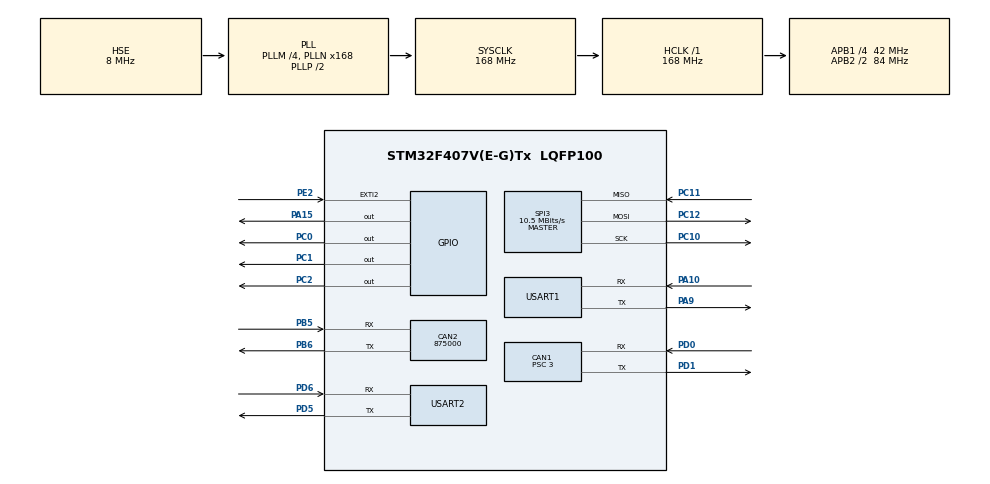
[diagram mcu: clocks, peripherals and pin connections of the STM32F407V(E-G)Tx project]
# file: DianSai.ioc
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CAN1.ABOM=DISABLE
CAN1.BS1=CAN_BS1_10TQ
CAN1.BS2=CAN_BS2_3TQ
CAN1.CalculateBaudRate=1000000
CAN1.CalculateTimeBit=1000
CAN1.CalculateTimeQuantum=71.42857142857143
CAN1.NART=DISABLE
CAN1.Prescaler=3
CAN1.SJW=CAN_SJW_1TQ
CAN2.BS1=CAN_BS1_1TQ
CAN2.BS2=CAN_BS2_1TQ
CAN2.CalculateBaudRate=875000
CAN2.CalculateTimeBit=1142
CAN2.CalculateTimeQuantum=380.95238095238096
Dma.Request0=USART1_TX
Dma.Request1=USART2_RX
Dma.Request2=USART2_TX
Dma.USART1_TX.0.Direction=DMA_MEMORY_TO_PERIPH
Dma.USART1_TX.0.FIFOMode=DMA_FIFOMODE_DISABLE
Dma.USART1_TX.0.Instance=DMA2_Stream7
Dma.USART1_TX.0.MemDataAlignment=DMA_MDATAALIGN_BYTE
Dma.USART1_TX.0.MemInc=DMA_MINC_ENABLE
Dma.USART1_TX.0.Mode=DMA_NORMAL
Dma.USART1_TX.0.PeriphDataAlignment=DMA_PDATAALIGN_BYTE
Dma.USART1_TX.0.PeriphInc=DMA_PINC_DISABLE
Dma.USART1_TX.0.Priority=DMA_PRIORITY_LOW
Dma.USART2_RX.1.Direction=DMA_PERIPH_TO_MEMORY
Dma.USART2_RX.1.FIFOMode=DMA_FIFOMODE_DISABLE
Dma.USART2_RX.1.Instance=DMA1_Stream5
Dma.USART2_RX.1.MemDataAlignment=DMA_MDATAALIGN_BYTE
Dma.USART2_RX.1.MemInc=DMA_MINC_ENABLE
Dma.USART2_RX.1.Mode=DMA_NORMAL
Dma.USART2_RX.1.PeriphDataAlignment=DMA_PDATAALIGN_BYTE
Dma.USART2_RX.1.PeriphInc=DMA_PINC_DISABLE
Dma.USART2_RX.1.Priority=DMA_PRIORITY_LOW
Dma.USART2_TX.2.Direction=DMA_MEMORY_TO_PERIPH
Dma.USART2_TX.2.FIFOMode=DMA_FIFOMODE_DISABLE
Dma.USART2_TX.2.Instance=DMA1_Stream6
Dma.USART2_TX.2.MemDataAlignment=DMA_MDATAALIGN_BYTE
Dma.USART2_TX.2.MemInc=DMA_MINC_ENABLE
Dma.USART2_TX.2.Mode=DMA_NORMAL
Dma.USART2_TX.2.PeriphDataAlignment=DMA_PDATAALIGN_BYTE
Dma.USART2_TX.2.PeriphInc=DMA_PINC_DISABLE
Dma.USART2_TX.2.Priority=DMA_PRIORITY_LOW
FREERTOS.Tasks01=defaultTask,0,128,StartDefaultTask,Default,NULL,Dynamic,NULL,NULL
Mcu.Family=STM32F4
Mcu.Name=STM32F407V(E-G)Tx
Mcu.Package=LQFP100
NVIC.CAN1_RX0_IRQn=true\:5\:0\:false\:false\:true\:true\:true\:true\:true
NVIC.CAN1_RX1_IRQn=true\:5\:0\:false\:false\:true\:true\:true\:true\:true
NVIC.CAN1_SCE_IRQn=true\:5\:0\:false\:false\:true\:true\:true\:true\:true
NVIC.CAN1_TX_IRQn=true\:5\:0\:false\:false\:true\:true\:true\:true\:true
NVIC.CAN2_RX0_IRQn=true\:5\:0\:true\:false\:true\:true\:true\:true\:true
NVIC.DMA1_Stream5_IRQn=true\:5\:0\:false\:false\:true\:true\:false\:true\:true
NVIC.DMA1_Stream6_IRQn=true\:5\:0\:false\:false\:true\:true\:false\:true\:true
NVIC.DMA2_Stream7_IRQn=true\:5\:0\:false\:false\:true\:true\:false\:true\:true
NVIC.EXTI2_IRQn=true\:6\:0\:true\:false\:true\:true\:true\:true\:true
NVIC.PriorityGroup=NVIC_PRIORITYGROUP_4
NVIC.TIM8_TRG_COM_TIM14_IRQn=true\:5\:0\:true\:false\:true\:false\:false\:true\:true
NVIC.TimeBase=TIM8_TRG_COM_TIM14_IRQn
NVIC.TimeBaseIP=TIM14
NVIC.USART1_IRQn=true\:5\:0\:false\:false\:true\:true\:true\:true\:true
NVIC.USART2_IRQn=true\:5\:0\:false\:false\:true\:true\:true\:true\:true
PA10.Mode=Asynchronous
PA10.Signal=USART1_RX
PA13.Mode=Serial_Wire
PA13.Signal=SYS_JTMS-SWDIO
PA14.Mode=Serial_Wire
PA14.Signal=SYS_JTCK-SWCLK
PA15.GPIO_Speed=GPIO_SPEED_FREQ_HIGH
PA15.Signal=GPIO_Output
PA9.Mode=Asynchronous
PA9.Signal=USART1_TX
PB5.Mode=CAN_Activate
PB5.Signal=CAN2_RX
PB6.Mode=CAN_Activate
PB6.Signal=CAN2_TX
PC0.Signal=GPIO_Output
PC1.Signal=GPIO_Output
PC10.Mode=Full_Duplex_Master
PC10.Signal=SPI3_SCK
PC11.Mode=Full_Duplex_Master
PC11.Signal=SPI3_MISO
PC12.Mode=Full_Duplex_Master
PC12.Signal=SPI3_MOSI
PC2.Signal=GPIO_Output
PD0.Mode=CAN_Activate
PD0.Signal=CAN1_RX
PD1.Mode=CAN_Activate
PD1.Signal=CAN1_TX
PD5.Mode=Asynchronous
PD5.Signal=USART2_TX
PD6.Mode=Asynchronous
PD6.Signal=USART2_RX
PE2.GPIO_ModeDefaultEXTI=GPIO_MODE_IT_RISING
PE2.GPIO_PuPd=GPIO_PULLUP
PE2.Signal=GPXTI2
PH0-OSC_IN.Mode=HSE-External-Oscillator
PH0-OSC_IN.Signal=RCC_OSC_IN
PH1-OSC_OUT.Mode=HSE-External-Oscillator
PH1-OSC_OUT.Signal=RCC_OSC_OUT
ProjectManager.HeapSize=0x200
ProjectManager.StackSize=0x400
ProjectManager.TargetToolchain=MDK-ARM V5.32
RCC.48MHZClocksFreq_Value=84000000
RCC.AHBFreq_Value=168000000
RCC.APB1CLKDivider=RCC_HCLK_DIV4
RCC.APB1Freq_Value=42000000
RCC.APB1TimFreq_Value=84000000
RCC.APB2CLKDivider=RCC_HCLK_DIV2
RCC.APB2Freq_Value=84000000
RCC.APB2TimFreq_Value=168000000
RCC.CortexFreq_Value=168000000
RCC.HCLKFreq_Value=168000000
RCC.HSE_VALUE=8000000
RCC.HSI_VALUE=16000000
RCC.LSE_VALUE=32768
RCC.PLLM=4
RCC.PLLN=168
RCC.PLLSourceVirtual=RCC_PLLSOURCE_HSE
RCC.SYSCLKFreq_VALUE=168000000
RCC.SYSCLKSource=RCC_SYSCLKSOURCE_PLLCLK
RCC.VCOOutputFreq_Value=336000000
SPI3.BaudRatePrescaler=SPI_BAUDRATEPRESCALER_4
SPI3.CalculateBaudRate=10.5 MBits/s
SPI3.Direction=SPI_DIRECTION_2LINES
SPI3.Mode=SPI_MODE_MASTER
SPI3.VirtualType=VM_MASTER
STMicroelectronics.X-CUBE-ALGOBUILD.1.5.0.LibraryCcDSPOoLibraryJjDSPOoLibrary=true
USART1.VirtualMode=VM_ASYNC
USART2.VirtualMode=VM_ASYNC
VP_FREERTOS_VS_CMSIS_V1.Mode=CMSIS_V1
VP_STMicroelectronics.X-CUBE-ALGOBUILD_VS_DSPOoLibraryJjLibrary_1.5.0_1.5.0.Mode=DSPOoLibraryJjLibrary
VP_SYS_VS_tim14.Mode=TIM14
board=custom

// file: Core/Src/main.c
/* USER CODE BEGIN Header */
/**
  ******************************************************************************
  * @file           : main.c
  * @brief          : Main program body
  ******************************************************************************
  * @attention
  *
  * Copyright (c) 2026 STMicroelectronics.
  * All rights reserved.
  *
  * This software is licensed under terms that can be found in the LICENSE file
  * in the root directory of this software component.
  * If no LICENSE file comes with this software, it is provided AS-IS.
  *
  ******************************************************************************
  */
/* USER CODE END Header */
#include "main.h"
#include "cmsis_os.h"
#include "can.h"
#include "dma.h"
#include "spi.h"
#include "usart.h"
#include "gpio.h"

/* USER CODE BEGIN Includes */
#include "main_task.h"
/* USER CODE END Includes */

void SystemClock_Config(void);
void MX_FREERTOS_Init(void);

int main(void)
{

  /* MCU Configuration--------------------------------------------------------*/

  /* Reset of all peripherals, Initializes the Flash interface and the Systick. */
  HAL_Init();

  /* Configure the system clock */
  SystemClock_Config();

  /* Initialize all configured peripherals */
  MX_GPIO_Init();
  MX_DMA_Init();
  MX_CAN1_Init();
  MX_CAN2_Init();
  MX_USART1_UART_Init();
  MX_USART2_UART_Init();
  MX_SPI3_Init();
  /* USER CODE BEGIN 2 */

  main_task_init();
  /* USER CODE END 2 */

  /* Call init function for freertos objects (in cmsis_os2.c) */
  MX_FREERTOS_Init();

  /* Start scheduler */
  osKernelStart();

  /* We should never get here as control is now taken by the scheduler */

  /* Infinite loop */
  while (1)
  {

  }
}

void SystemClock_Config(void)
{
  RCC_OscInitTypeDef RCC_OscInitStruct = {0};
  RCC_ClkInitTypeDef RCC_ClkInitStruct = {0};

  /** Configure the main internal regulator output voltage
  */
  __HAL_RCC_PWR_CLK_ENABLE();
  __HAL_PWR_VOLTAGESCALING_CONFIG(PWR_REGULATOR_VOLTAGE_SCALE1);

  /** Initializes the RCC Oscillators according to the specified parameters
  * in the RCC_OscInitTypeDef structure.
  */
  RCC_OscInitStruct.OscillatorType = RCC_OSCILLATORTYPE_HSE;
  RCC_OscInitStruct.HSEState = RCC_HSE_ON;
  RCC_OscInitStruct.PLL.PLLState = RCC_PLL_ON;
  RCC_OscInitStruct.PLL.PLLSource = RCC_PLLSOURCE_HSE;
  RCC_OscInitStruct.PLL.PLLM = 4;
  RCC_OscInitStruct.PLL.PLLN = 168;
  RCC_OscInitStruct.PLL.PLLP = RCC_PLLP_DIV2;
  RCC_OscInitStruct.PLL.PLLQ = 4;
  if (HAL_RCC_OscConfig(&RCC_OscInitStruct) != HAL_OK)
  {
    Error_Handler();
  }

  /** Initializes the CPU, AHB and APB buses clocks
  */
  RCC_ClkInitStruct.ClockType = RCC_CLOCKTYPE_HCLK|RCC_CLOCKTYPE_SYSCLK
                              |RCC_CLOCKTYPE_PCLK1|RCC_CLOCKTYPE_PCLK2;
  RCC_ClkInitStruct.SYSCLKSource = RCC_SYSCLKSOURCE_PLLCLK;
  RCC_ClkInitStruct.AHBCLKDivider = RCC_SYSCLK_DIV1;
  RCC_ClkInitStruct.APB1CLKDivider = RCC_HCLK_DIV4;
  RCC_ClkInitStruct.APB2CLKDivider = RCC_HCLK_DIV2;

  if (HAL_RCC_ClockConfig(&RCC_ClkInitStruct, FLASH_LATENCY_5) != HAL_OK)
  {
    Error_Handler();
  }
}

void HAL_TIM_PeriodElapsedCallback(TIM_HandleTypeDef *htim)
{
  if (htim->Instance == TIM14)
  {
    HAL_IncTick();
  }
}

void Error_Handler(void)
{
  __disable_irq();
  while (1)
  {
  }
}
